# STM32C551 register map
File version: 1.0.0
CPU: CM33 r0p4, little endian, MPU, FPU, 4 interrupt priority bits
Registers are 32-bit, read-write, reset 0x0 unless marked. A register's access mark holds for its fields unless they carry their own. Offsets are from the block's base; [hi:lo] are bit positions; 'fields as' and 'values as' point back to an identical list.

## FLASH — FLASH address block description
Base 0x40022000
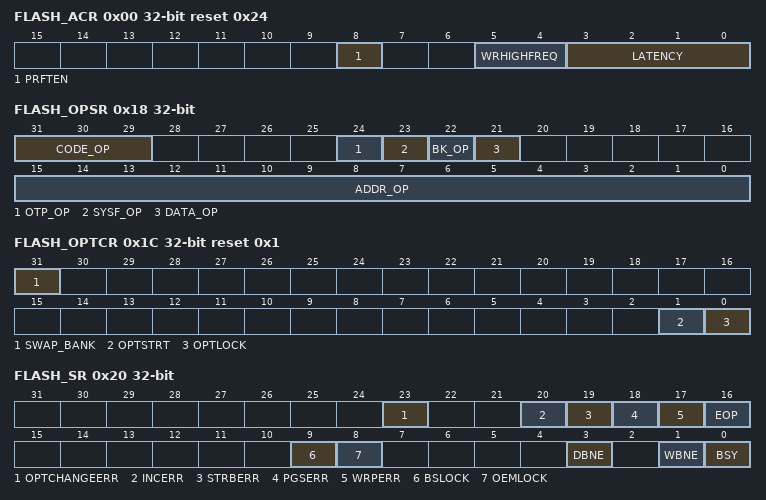
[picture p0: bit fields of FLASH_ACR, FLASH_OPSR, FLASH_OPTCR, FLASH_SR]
0x00 FLASH_ACR reset 0x24 — Each register is assigned a offset address and a reset value.
  [8] PRFTEN — Prefetch enable
    0=prefetch disabled; 1=prefetch enabled when latency is at least one wait-state
  [5:4] WRHIGHFREQ — FLASH signal delay
  [3:0] LATENCY — Read latency
    0=zero wait state used to read a word from non-volatile memory; 1=one wait state used to read a word from non-volatile memory; 2=two wait states used to read a word from non-volatile memory; 7=seven wait states used to read a word from non-volatile memory; 15=15 wait states used to read from non-volatile memory
0x04 FLASH_KEYR wo — FLASH key register
  [31:0] KEY — Non-volatile memoryconfiguration access unlock key
0x0C FLASH_OPTKEYR wo — FLASH option key register
  [31:0] OPTKEY — FLASH option-byte control access unlock key
0x18 FLASH_OPSR ro reset not defined — FLASH operation status register
  [31:29] CODE_OP — Flash memory operation code
    0=No FLASH operation ongoing during previous reset; 1=Single write operation interrupted; 3=Sector erase operation interrupted; 4=Bank erase operation interrupted; 5=Mass erase operation interrupted; 6=Option change operation interrupted
  [24] OTP_OP — OTP operation interrupted
  [23] SYSF_OP — Operation in system flash memory interrupted
  [22] BK_OP — Interrupted operation bank
  [21] DATA_OP — Flash data area operation interrupted
  [15:0] ADDR_OP — Interrupted operation address
0x1C FLASH_OPTCR reset 0x1 (reset mask 0xFFFFFFF) — FLASH option control register
  [31] SWAP_BANK ro — Bank swapping option configuration bit
    0=Bank1 and bank2 not swapped; 1=Bank1 and bank2 swapped
  [1] OPTSTRT — Option-byte start change option configuration bit
  [0] OPTLOCK — FLASH_OPTCR lock option configuration bit
    0=FLASH_OPTCR register unlocked; 1=FLASH_OPTCR register locked
0x20 FLASH_SR ro (reset mask 0xFFFFFFF0) — FLASH status register
  [23] OPTCHANGEERR — Option-byte change error flag
    0=no option-byte change errors occurred; 1=one or more errors occurred during an option-byte change operation
  [20] INCERR — Inconsistency error flag
    0=no inconsistency error occurs; 1=a inconsistency error occurs
  [19] STRBERR — strobe error flag
    0=no strobe error occurred; 1=a strobe error occurred
  [18] PGSERR — programming sequence error flag
    0=no sequence error occurred; 1=a sequence error occurred
  [17] WRPERR — write protection error flag
    0=no write protection error occurred; 1=a write protection error occurred
  [16] EOP — end of operation flag
    0=no operation completed; 1=a operation completed
  [9] BSLOCK
  [8] OEMLOCK
  [3] DBNE — data buffer not empty flag
    0=data buffer not used; 1=data buffer used, wait
  [1] WBNE — write buffer not empty flag
    0=write buffer empty or full; 1=write buffer waiting data to complete
  [0] BSY — busy flag
    0=no programming, erase or option byte change operation being executed; 1=programming, erase or option byte change operation being executed
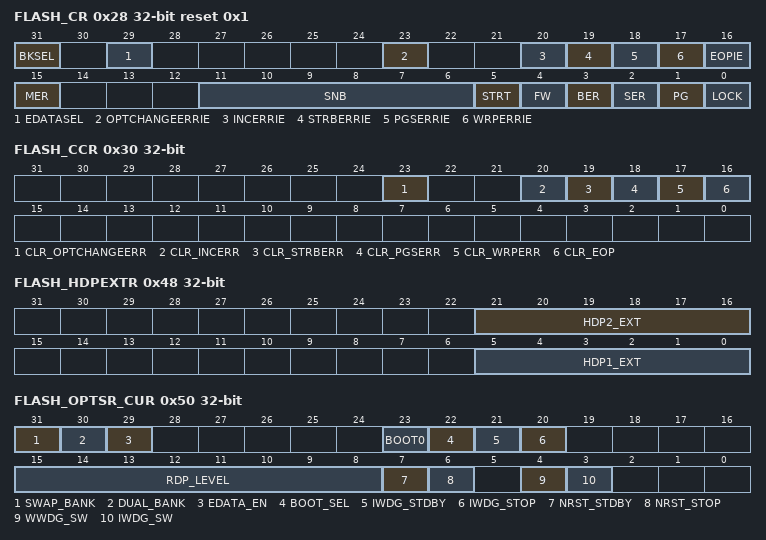
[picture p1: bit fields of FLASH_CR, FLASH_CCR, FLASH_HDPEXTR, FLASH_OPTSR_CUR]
0x28 FLASH_CR reset 0x1 — FLASH control register
  [31] BKSEL — Bank selector bit
    0=Bank1 is selected for bank erase (BER)/sector erase (SER)/interrupt enable; 1=Bank2 is selected for BER/SER
  [29] EDATASEL — EDATA erase selector bit
    0=Main flash sector erase; 1=Flash data area EDATA sector erase
  [23] OPTCHANGEERRIE — Option-byte change error interrupt enable bit
    0=no interrupt is generated when an error occurs during an option-byte change; 1=an interrupt is generated when and error occurs during an option-byte change
  [20] INCERRIE — inconsistency error interrupt enable bit
    0=no interrupt generated when a inconsistency error occurs; 1=interrupt generated when a inconsistency error occurs
  [19] STRBERRIE — strobe error interrupt enable bit
    0=no interrupt generated when a strobe error occurs; 1=interrupt generated when strobe error occurs
  [18] PGSERRIE — programming sequence error interrupt enable bit
    0=no interrupt generated when a sequence error occurs; 1=interrupt generated when sequence error occurs
  [17] WRPERRIE — write protection error interrupt enable bit
    0=no interrupt generated when a protection error occurs; 1=interrupt generated when a protection error occurs
  [16] EOPIE — end of operation interrupt control bit
    0=no interrupt generated at the end of operation; 1=interrupt enabled when at the end of operation
  [15] MER — Mass erase request
    0=mass erase not requested; 1=mass erase requested
  [11:6] SNB — sector erase selection number
    0=Sector 0 selected; 1=Sector 1 selected; 47=Sector 41 selected
  [5] STRT — erase start control bit
  [4] FW — write forcing control bit
  [3] BER — erase request
    0=bank erase not requested; 1=bank erase requested
  [2] SER — sector erase request
    0=sector erase not requested; 1=sector erase requested
  [1] PG — programming control bit
    0=programming disabled; 1=programming enabled
  [0] LOCK — configuration lock bit
    0=FLASH_CR register unlocked; 1=FLASH_CR register locked
0x30 FLASH_CCR wo — FLASH clear control register
  [23] CLR_OPTCHANGEERR — Clear the flag corresponding flag in FLASH_SR by writing this bit.
  [20] CLR_INCERR — INCERR flag clear bit
  [19] CLR_STRBERR — STRBERR flag clear bit
  [18] CLR_PGSERR — PGSERR flag clear bit
  [17] CLR_WRPERR — WRPERR flag clear bit
  [16] CLR_EOP — EOP flag clear bit
0x3C FLASH_PRIVCFGR — FLASH privilege configuration register
  [1] PRIV — privilege attribute
    0=Access to registers is always granted; 1=Access to registers is denied in case of unprivileged access
0x48 FLASH_HDPEXTR — FLASH HDP extension register
  [21:16] HDP2_EXT — HDP area extension in 8Kbytes sectors in bank2.
  [5:0] HDP1_EXT — HDP area extension in 8Kbytes sectors in bank1.
0x50 FLASH_OPTSR_CUR ro reset not defined — FLASH option status register
  [31] SWAP_BANK — Bank swapping option status bit
    0=Bank1 and bank2 not swapped; 1=Bank1 and bank2 swapped
  [30] DUAL_BANK — Dual bank selection option status bit
    0=256Kbytes of user flash located in one bank; 1=256Kbytes of user flash split with 128Kbytes in Bank 1 and 128Kbytes in Bank 2
  [29] EDATA_EN — Flash data area enable
    0=No flash data area (EDATA sectors are 128 bits writable); 1=Flash data area is enabled (EDATA sectors are 16/32 bits writable)
  [23] BOOT0 — Boot 0 option bit
    0=BOOT0 = 0; 1=BOOT0 = 1
  [22] BOOT_SEL — Boot 0 source selection
    0=BOOT0 signal is defined by the BOOT0 option bit; 1=BOOT0 signal is defined by BOOT0 pin value (legacy mode)
  [21] IWDG_STDBY — IWDG Standby mode freeze option status bit
    0=Independent watchdog frozen in Standby mode; 1=Independent watchdog keep running in Standby mode
  [20] IWDG_STOP — IWDG Stop mode freeze option status bit
    0=Independent watchdog frozen in system Stop mode; 1=Independent watchdog keep running in system Stop mode
  [15:8] RDP_LEVEL — RDP level code (based on Hamming 8,4).
  [7] NRST_STDBY — Core domain Standby entry reset option status bit
    0=a reset is generated when entering Standby mode on core domain; 1=no reset generated when entering Standby mode on core domain
  [6] NRST_STOP — Core domain Stop entry reset option status bit
    0=a reset is generated when entering Stop mode on core domain; 1=no reset generated when entering Stop mode on core domain
  [4] WWDG_SW — WWDG control mode option status bit
    0=WWDG watchdog is controlled by hardware; 1=WWDG watchdog is controlled by software
  [3] IWDG_SW — IWDG control mode option status bit
    0=IWDG watchdog is controlled by hardware; 1=IWDG watchdog is controlled by software
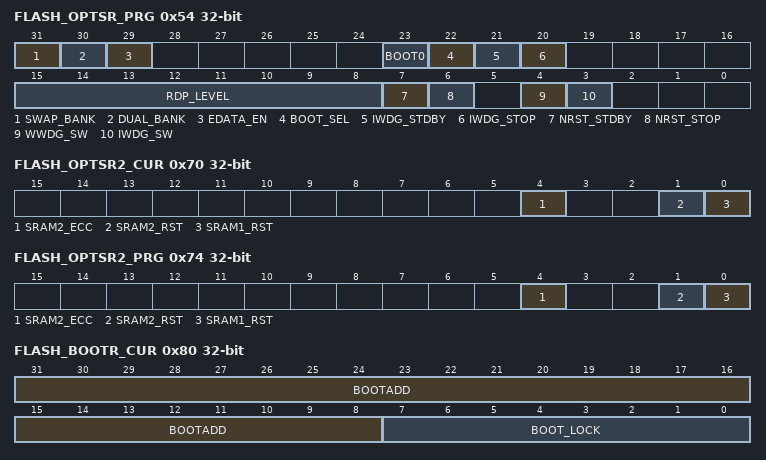
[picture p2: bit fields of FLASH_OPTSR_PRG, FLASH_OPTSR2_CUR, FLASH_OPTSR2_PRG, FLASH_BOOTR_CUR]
0x54 FLASH_OPTSR_PRG reset not defined — FLASH option status register
  [31] SWAP_BANK — Bank swapping option configuration bit
    0=Bank1 and bank2 not swapped; 1=Bank1 and bank2 swapped
  [30] DUAL_BANK — Dual bank option configuration bit
    values as FLASH_OPTSR_CUR.DUAL_BANK
  [29] EDATA_EN — Flash data area enable
    0=No flash data area; 1=Flash data area is enabled
  [23] BOOT0 — Boot 0 option bit
    0=BOOT0 = 0; 1=BOOT0 = 1
  [22] BOOT_SEL — Boot 0 source configuration
    values as FLASH_OPTSR_CUR.BOOT_SEL
  [21] IWDG_STDBY — IWDG Standby mode freeze option configuration bit
    values as FLASH_OPTSR_CUR.IWDG_STDBY
  [20] IWDG_STOP — IWDG Stop mode freeze option configuration bit
    values as FLASH_OPTSR_CUR.IWDG_STOP
  [15:8] RDP_LEVEL — RDP level code (based on Hamming 8,4).
  [7] NRST_STDBY — Core domain Standby entry reset option configuration bit
    values as FLASH_OPTSR_CUR.NRST_STDBY
  [6] NRST_STOP — Core domain Stop entry reset option configuration bit
    values as FLASH_OPTSR_CUR.NRST_STOP
  [4] WWDG_SW — WWDG control mode option configuration bit
    values as FLASH_OPTSR_CUR.WWDG_SW
  [3] IWDG_SW — IWDG control mode option configuration bit
    values as FLASH_OPTSR_CUR.IWDG_SW
0x70 FLASH_OPTSR2_CUR ro reset not defined — FLASH option status register 2
  [4] SRAM2_ECC — SRAM2 ECC detection and correction disable
    0=SRAM2 ECC check enabled; 1=SRAM2 ECC check disabled
  [1] SRAM2_RST — SRAM2 erase when system reset
    0=SRAM2 erased when a system reset occurs; 1=SRAM2 not erased when a system reset occurs
  [0] SRAM1_RST — SRAM1 erase upon system reset
    0=SRAM1 erased when a system reset occurs; 1=SRAM1 not erased when a system reset occurs
0x74 FLASH_OPTSR2_PRG reset not defined — FLASH option status register 2
  fields as FLASH_OPTSR2_CUR
0x80 FLASH_BOOTR_CUR ro reset not defined — FLASH unique boot entry register
  [31:8] BOOTADD — unique boot entry address
  [7:0] BOOT_LOCK — A field locking the values of SWAP_BANK, and BOOTADD settings.
    195=The SWAP_BANK and BOOTADD can still be modified following their individual rules; 180=The SWAP_BANK and BOOTADD are frozen
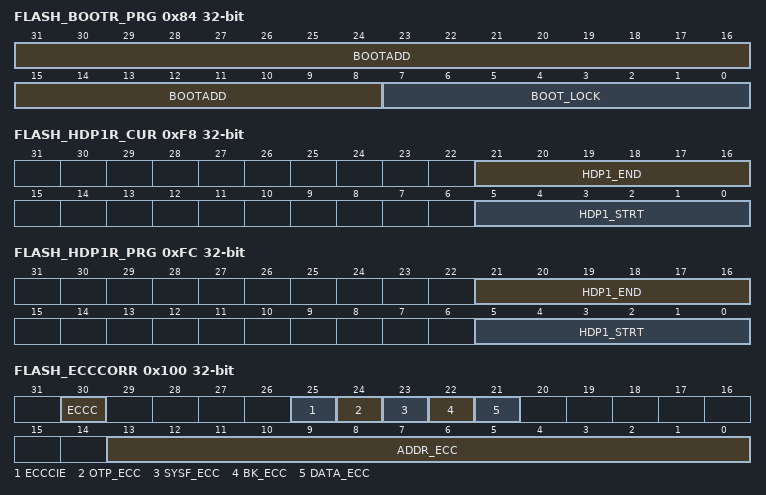
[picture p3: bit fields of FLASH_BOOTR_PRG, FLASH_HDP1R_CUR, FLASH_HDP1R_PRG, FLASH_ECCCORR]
0x84 FLASH_BOOTR_PRG ro reset not defined — FLASH unique boot entry address
  fields as FLASH_BOOTR_CUR
0x90 FLASH_OTPBLR_CUR ro (reset mask 0xFF000000) — FLASH OTP block lock
  [23:0] LOCKBL — OTP block lock
0x94 FLASH_OTPBLR_PRG (reset mask 0xFF000000) — FLASH OTP block lock
  [23:0] LOCKBL — OTP block lock
0xA4 FLASH_OEMKEYR1_PRG wo reset not defined — FLASH OEM Key register 1
  [31:0] OEMKEY — Least significants bytes of OEMKEY
0xAC FLASH_OEMKEYR2_PRG wo reset not defined — FLASH OEM Key register 2
  [31:0] OEMKEY — Mid-least significants bytes of OEMKEY
0xB4 FLASH_OEMKEYR3_PRG wo reset not defined — FLASH OEM Key register 3
  [31:0] OEMKEY — Mid-most significants bytes of OEMKEY
0xBC FLASH_OEMKEYR4_PRG wo reset not defined — FLASH OEM Key register 4
  [31:0] OEMKEY — Most significants bytes of OEMKEY
0xC4 FLASH_BSKEYR_PRG wo reset not defined — FLASH Boundary Scan key register
  [31:0] BSKEY — Boundary Scan KEY
0xE8 FLASH_WRP1R_CUR ro reset not defined — FLASH write sector protection for bank1
  [31:0] WRPSG1 — Bank1 sector protection option status byte
    0=write protected;; 1=not write protected
0xEC FLASH_WRP1R_PRG reset not defined — FLASH write sector protection for bank1
  fields as FLASH_WRP1R_CUR
0xF8 FLASH_HDP1R_CUR ro reset not defined — FLASH HDP bank1 register
  [21:16] HDP1_END — HDPL barrier end set in number of 8Kbytes sectors
  [5:0] HDP1_STRT — HDPL barrier start set in number of 8Kbytes sectors
0xFC FLASH_HDP1R_PRG reset not defined — FLASH HDP bank1 register
  [21:16] HDP1_END — Bank 1 HDPL barrier end set in number of 8Kbytes sectors
  [5:0] HDP1_STRT — Bank 1 HDPL barrier start set in number of 8Kbytes sectors
0x100 FLASH_ECCCORR — FLASH ECC correction register
  [30] ECCC — ECC correction
  [25] ECCCIE — ECC single correction error interrupt enable bit When ECCCIE bit is set to 1, an interrupt is generated when an ECC single correction error occurs during a read operation.
    0=no interrupt generated when an ECC single correction error occurs; 1=interrupt generated when an ECC single correction error occurs
  [24] OTP_ECC ro — OTP ECC error bit
  [23] SYSF_ECC ro — ECC flag for corrected ECC error in system FLASH
  [22] BK_ECC ro — ECC bank flag for corrected ECC error
  [21] DATA_ECC ro — ECC fail for corrected ECC error in flash data area
  [13:0] ADDR_ECC ro — ECC error address
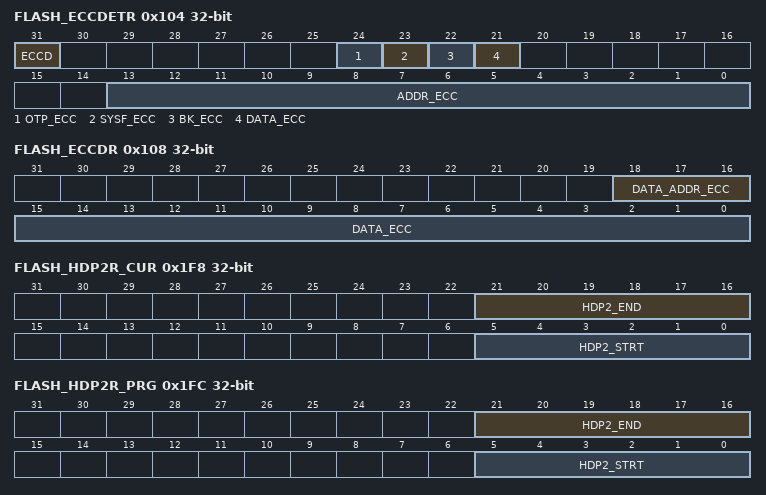
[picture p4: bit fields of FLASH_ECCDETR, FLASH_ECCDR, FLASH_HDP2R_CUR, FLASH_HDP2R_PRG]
0x104 FLASH_ECCDETR — FLASH ECC detection register
  [31] ECCD — ECC detection set by hardware when two ECC error has been detected.
  [24] OTP_ECC ro — OTP ECC error bit
  [23] SYSF_ECC ro — ECC fail for double ECC error in system flash memory
  [22] BK_ECC ro — ECC fail bank for double ECC Error
  [21] DATA_ECC ro — ECC fail for double ECC error in flash data area
  [13:0] ADDR_ECC ro — ECC error address
0x108 FLASH_ECCDR ro — FLASH ECC data
  [18:16] DATA_ADDR_ECC — DATA ECC error address
  [15:0] DATA_ECC — ECC error data
0x1E8 FLASH_WRP2R_CUR ro reset not defined — FLASH write sector protection for bank2
  [31:0] WRPSG2 — Bank2 sector protection option status byte
    0=write protected;; 1=not write protected
0x1EC FLASH_WRP2R_PRG reset not defined — FLASH write sector protection for bank2
  fields as FLASH_WRP2R_CUR
0x1F8 FLASH_HDP2R_CUR ro reset not defined — FLASH HDP bank2 register
  [21:16] HDP2_END — Bank 2 HDPL barrier end set in number of 8Kbytes sectors
  [5:0] HDP2_STRT — Bank 2 HDPL barrier start set in number of 8Kbytes sectors
0x1FC FLASH_HDP2R_PRG reset not defined — FLASH HDP bank2 register
  fields as FLASH_HDP2R_CUR

## Notices in the file
Copyright (c) 2026 STMicroelectronics.
SPDX-License-Identifier: Apache-2.0
Licensed under the Apache License, Version 2.0 (the "License");
you may not use this file except in compliance with the License.
You may obtain a copy of the License at
http://www.apache.org/licenses/LICENSE-2.0
Unless required by applicable law or agreed to in writing, software
distributed under the License is distributed on an "AS IS" BASIS,
WITHOUT WARRANTIES OR CONDITIONS OF ANY KIND, either express or implied.
See the License for the specific language governing permissions and
limitations under the License.
